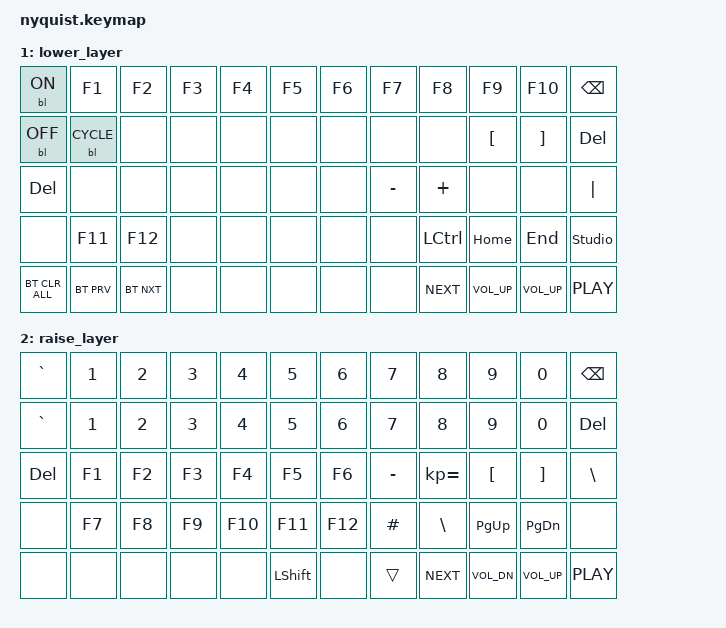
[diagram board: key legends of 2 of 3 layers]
#include <behaviors.dtsi>
#include <dt-bindings/zmk/keys.h>
#include <dt-bindings/zmk/bt.h>
#include <dt-bindings/zmk/backlight.h>

/ {
    keymap {
        compatible = "zmk,keymap";
        default_layer {
            //  -------------------------------------------------------------------------------------------------
            // |  GRAV |  1   |  2   |  3   |  4    |  5     |   6     |  7     |  8   |  9    |   0   | BSPC   |
            // |  TAB  |  Q   |  W   |  E   |  R    |  T     |   Y     |  U     |  I   |  O    |   P   | DEL    |
            // |  ESC  |  A   |  S   |  D   |  F    |  G     |   H     |  J     |  K   |  L    |   ;   |  '     |
            // | SHIFT |  Z   |  X   |  C   |  V    |  B     |   N     |  M     |  ,   |  .    |   /   | RET    |
            // |       | LGUI | LALT | LCTL | LOWER | SPACE  |  SPACE  |  RAISE | LEFT |  DOWN |   UP  | RIGHT  |
            bindings = <
                &kp GRAVE   &kp N1     &kp N2    &kp N3    &kp N4     &kp N5     &kp N6     &kp N7     &kp N8     &kp N9    &kp N0     &kp BSPC
                &kp TAB     &kp Q      &kp W &kp &kp E     &kp R      &kp T      &kp Y      &kp U      &kp I      &kp O     &kp P      &kp SQT
                &kp ESC     &kp A      &kp S     &kp D     &kp F      &kp G      &kp H      &kp J      &kp K      &kp L     &kp SEMI   &kp RET
                &kp LSHIFT  &kp Z      &kp X     &kp C     &kp V      &kp B      &kp N      &kp M      &kp COMMA  &kp DOT   &kp SLASH  &kp UP
                &kp LCTRL   &kp LGUI   &kp LALT  &mo 1     &kp SPACE                        &kp SPACE  &mo 2  &kp LEFT  &kp RIGHT  &kp DOWN
                >;
        };
        lower_layer {
            // ------------------------------------------------------------------------------------------
            // |   ~   |  !   |  @   |  #   |  $   |  %   |   ^   |   &   |   *  |  (   |   )   | BSPC  |
            // |   ~   |  !   |  @   |  #   |  $   |  %   |   ^   |   &   |   *  |  (   |   )   | DEL   |
            // |  DEL  |  F1  |  F2  |  F3  |  F4  |  F5  |  F6   |   -   |   +  |  [   |   ]   |  |    |
            // |       |  F7  |  F8  |  F9  |  F10 |  F11 |  F12  |       | LCTL | HOME |  END  |       |
            // | LALT  |      |      |      |      |      |       |       | NEXT | VOL- | VOL+  | PLAY  |
            bindings = <
                &bl BL_ON      &kp F1       &kp F2      &kp F3      &kp F4      &kp F5      &kp F6      &kp F7      &kp F8      &kp F9            &kp F10            &kp BSPC
                &bl BL_OFF     &bl BL_CYCLE &none       &none       &none       &none       &none       &none       &none       &kp LEFT_BRACKET  &kp RIGHT_BRACKET  &kp DEL
                &kp DEL        &none        &none       &none       &none       &none       &none       &kp MINUS   &kp PLUS    &none             &none              &kp PIPE
                &none          &kp F11      &kp F12     &none       &none       &none       &none       &none       &kp LCTRL   &kp HOME          &kp END            &studio_unlock
                &bt BT_CLR_ALL &bt BT_PRV   &bt BT_NXT  &none       &none       &none       &none       &none       &kp C_NEXT  &kp C_VOL_UP      &kp C_VOL_UP       &kp C_PLAY
                >;
        };
        raise_layer {
            // -------------------------------------------------------------------------------------------
            // |   `   |  1   |  2   |  3   |  4   |   5   |   6   |   7   |   8  |  9   |   0   | BSPC  |
            // |   `   |  1   |  2   |  3   |  4   |   5   |   6   |   7   |   8  |  9   |   0   | DEL   |
            // |  DEL  |  F1  |  F2  |  F3  |  F4  |  F5   |  F6   |   -   |   =  |  [   |   ]   |  \    |
            // |       |  F7  |  F8  |  F9  |  F10 |  F11  |  F12  |   #   |   \  | PGUP |  PGDN |       |
            // |       |      |      |      |      | SHIFT |       |       | NEXT | VOL- |  VOL+ | PLAY  |
            bindings = <
                &kp GRAVE  &kp N1  &kp N2  &kp N3  &kp N4   &kp N5      &kp N6   &kp N7     &kp N8        &kp N9            &kp N0             &kp BSPC
                &kp GRAVE  &kp N1  &kp N2  &kp N3  &kp N4   &kp N5      &kp N6   &kp N7     &kp N8        &kp N9            &kp N0             &kp DEL
                &kp DEL    &kp F1  &kp F2  &kp F3  &kp F4   &kp F5      &kp F6   &kp MINUS  &kp KP_EQUAL  &kp LEFT_BRACKET  &kp RIGHT_BRACKET  &kp BSLH
                &none      &kp F7  &kp F8  &kp F9  &kp F10  &kp F11     &kp F12  &kp HASH   &kp BSLH      &kp PG_UP         &kp PG_DN          &none
                &none      &none   &none   &none   &none    &kp LSHIFT  &none    &trans     &kp C_NEXT    &kp C_VOL_DN      &kp C_VOL_UP       &kp C_PLAY
                >;
        };
    };
};
